# pse84_a0 register map
Vendor: Infineon Technologies; Series: PSE84_A0; File version: 1.0
CPU: CM33 r0p1, little endian, MPU, FPU, VTOR, 3 interrupt priority bits
Registers are 32-bit, read-write, reset 0x0 unless marked. A register's access mark holds for its fields unless they carry their own. Offsets are from the block's base; [hi:lo] are bit positions; lines under a group give offsets from that group.

## USBHS (part 7 of 7) — Regmap for both Subsystem and Controller IP
Base 0x44900000
0x40000 SS group — USBHS Subsystem, Controller, PHY control,configuration and status registers
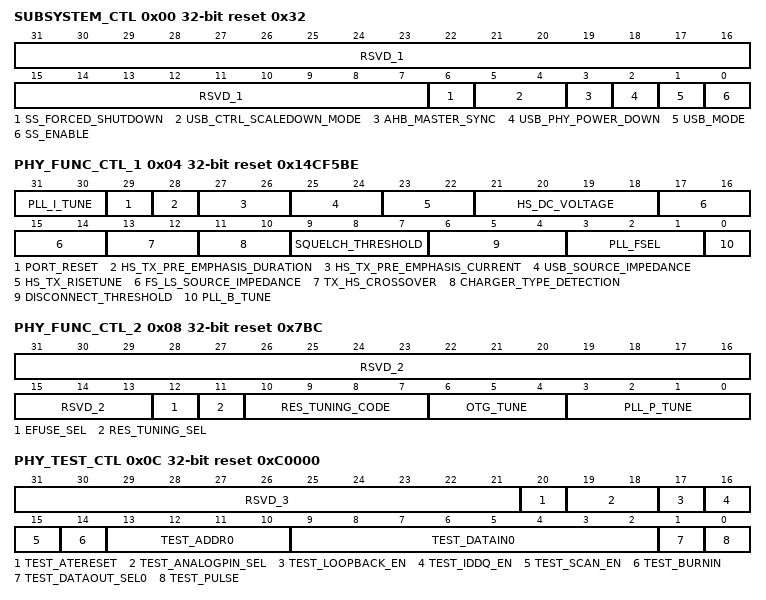
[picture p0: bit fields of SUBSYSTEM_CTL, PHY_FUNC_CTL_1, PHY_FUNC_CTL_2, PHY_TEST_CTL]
  0x00 SUBSYSTEM_CTL reset 0x32 — Subsystem level control register
    [31:7] RSVD_1
    [6] SS_FORCED_SHUTDOWN — 1'b1: Forces shutdown of Controller resulting in data corruption from/to of Controller to the PHY resulting in USBHS moving to Q-state by accepting Q-channel request. 1'b0: Subsystem in normal operational mode.
    [5:4] USB_CTRL_SCALEDOWN_MODE — 2'b00: Disables all scale-downs,actual timing value are used for synthesis.2'b01:Enables scale-down of all timing except Device mode.2'b10:Enables scale-down of Device mode suspend and resume timing values only.2'b11:Enables bit 0 and 1 scale-down timing values useful for simulations
    [3] AHB_MASTER_SYNC — 1'b1:Enables AHB Master interface of Controller synchronisation to 'mmio_clk_hf' clock.1'b0: Disables AHB5 Master interface synchronisation such that 100 MHz generated out of 'clk_hf' is used.
    [2] USB_PHY_POWER_DOWN — 1'b1:In the PHY during Sleep , the bias,PLL blocks are powered down and in Suspend , REFCLK_LOGIC also powered down. 1'b0:All the three blocks remain powered during Sleep and Suspend modes.
    [1] USB_MODE — 1'b1:USB Subsystem is set to Host mode.1'b0: Subsystem is set to Device mode.
    [0] SS_ENABLE — 1'b1: Subsystem enable after power on reset to indicate both analog and digital power supply,all top level clocks,resets are stable to configure Controller core mode. 1'b0: Subsystem disable
  0x04 PHY_FUNC_CTL_1 reset 0x14CF5BE — Subsystem level- PHY functional mode control register 1
    [31:30] PLL_I_TUNE — PHY PLL Integral path tune.2'b00:1.0x ,2'b01:2.0x,2'b10:3.0x,2'b11:4.0x
    [29] PORT_RESET — PHY port reset. 1'b0:Transmitter ,Receiver FSMs are operational and line_state becomes sequential after 11 PHY clock cycles. 1'b1:Transmitter ,Receiver FSMs are reset and line_state combinatorily reflects the state of SE-receivers.
    [28] HS_TX_PRE_EMPHASIS_DURATION — HS transmitter pre-emphasis duration control. 1'b0:2x long pre-emphasis, 1'b1:1x short pre-emphasis.
    [27:26] HS_TX_PRE_EMPHASIS_CURRENT — HS transmitter pre-emphasis current control. 2'b00:0 ,2'b01:1x,2'b10:2x,2'b11:3x
    [25:24] USB_SOURCE_IMPEDANCE — USB source impedance (Ohm). 2'b00:+3.01, 2'b01:0, 2'b10:2.68, 2'b11:5.01
    [23:22] HS_TX_RISETUNE — HS transmitter rise/fall time( percent).2'b00:+1.06, 2'b01:0, 2'b10:-1.9, 2'b11:-2.33
    [21:18] HS_DC_VOLTAGE — HS DC voltage( percent) level adjustment.4'b000:-6.06,4'b0001:-4.04,4'b0010:-2.03,4'b0011:0
    [17:14] FS_LS_SOURCE_IMPEDANCE
    [13:12] TX_HS_CROSSOVER
    [11:10] CHARGER_TYPE_DETECTION — Data detect voltage threshold adjustment during charger type detection. 2'b00:+10.2 percent , 2'b01:0 percent, 2'b10:-10.2 percent, 2'b11: -20.75 percent
    [9:7] SQUELCH_THRESHOLD — Voltage level threshold to detect valid High-Speed data. 3'b000 : +16.9 percent , 3'b001: +10.95 percent , 3'b010: +5.86 percent, 3'b011:0 percent,3'b100: -5.03 percent, 3'b101: -11.41 percent, 3'b110 : -16.92 percent ,3'b111: -22.75 percent.
    [6:4] DISCONNECT_THRESHOLD — Voltage level threshold to detect a disconnect event. 3'b000 : -4.33 percent , 3'b001: -2.93 percent , 3'b010: -1.48 percent, 3'b011:0 percent,3'b100: +1.36 percent, 3'b101: + 2.98 percent, 3'b110 : +4.67 percent ,3'b111: +6.45 percent.
    [3:1] PLL_FSEL — PHY PLL reference clock frequency selection(MHz). If BANDWIDTH_TUNE is 1'b0 ,then 3'b000 is 9.6, 3'b001 is 10, 3'b010 is 12 and 3'b111 is 50 .Else 3'b000 is 19.2, 3'b001 is 20, 3'b010 is 24. Other combination of values are invlaid.
    [0] PLL_B_TUNE — PHY PLL reference clock frequency tuning enable to double bandwidth of the PLL 1'b1: Enable ,1'b0: Disable
  0x08 PHY_FUNC_CTL_2 reset 0x7BC — Subsystem level- PHY functional mode control register 2
    [31:13] RSVD_2
    [12] EFUSE_SEL — This signal selects the tuning method for the high-speed DP0 and DM0 source impedance of the USB 2.0 femtoPHY.1: Internal digital calibration code is used for tuning the high-speed source impedance.0: The RCALCODE0[3:0] value is used for tuning the high-speed source impedance.
    [11] RES_TUNING_SEL — This signal selects the tuning method for the high-speed DP0 and DM0 source impedance of the USB 2.0 femtoPHY.1: Internal digital calibration code is used for tuning the high-speed source impedance.0: The RCALCODE0[3:0] value is used for tuning the high-speed source impedance.
    [10:7] RES_TUNING_CODE — This bus is the resistor tuning code for the high-speed DP0 and DM0 source impedance of the USB 2.0 femtoPHY. The input values for this bus could be driven by ATE during characterization or production, and by an EFUSE block during product operation. All values from 4'b1111 to 4'b0000 are valid.4'b1111: provides lowest impedance on DP0 and DM0.4'b0000: provides the highest impedance on DP0 and DM0
    [6:4] OTG_TUNE — VBUS Valid Threshold Adjustment.3'b011: 0, (design default)
    [3:0] PLL_P_TUNE — PHY PLL Proportioanl path tune.4'b1100:10.0x(design default)
  0x0C PHY_TEST_CTL reset 0xC0000 — Subsystem level- PHY test mode control register
    [31:21] RSVD_3
    [20] TEST_ATERESET — USB PHY test mode ATE reset. 1'b1 : Disables PHYCLOCK0 ,FREECLK outputs. 1'b0:PHYCLOCK0 ,FREECLK outputs are available within(maximum duration) 16.33 ns if UTMI+ interface is 8 bits else 24.66 ns
    [19:18] TEST_ANALOGPIN_SEL
    [17] TEST_LOOPBACK_EN — USB PHY loopback test control 1'b1: Enable.1'b0:Disable
    [16] TEST_IDDQ_EN — USB PHY IDDQ test control 1'b1: Enable.1'b0:Disable
    [15] TEST_SCAN_EN — USB PHY scan test (at-speed and stuck-at fault)mode. 1'b1: Enable.1'b0:Disable
    [14] TEST_BURNIN — USB PHY test mode burn-in control. 1'b1: Enable(PHY performs power on reset,enters HS loopback mode to transmit alternate 1's and 0's until disabled. 1'b0:Disable
    [13:10] TEST_ADDR0 — USB PHY test mode register address bus.
    [9:2] TEST_DATAIN0 — USB PHY test mode data write bus. Bits 0 to 3 are data, 4 to 7 are corresponding write enables
    [1] TEST_DATAOUT_SEL0 — USB PHY test mode data output selection. 1'b1: Mode-defined test register contents are output. 1'b0:Mode-defined, internally generated signals are ouptut.
    [0] TEST_PULSE — USB PHY test mode non-continous clocking signal
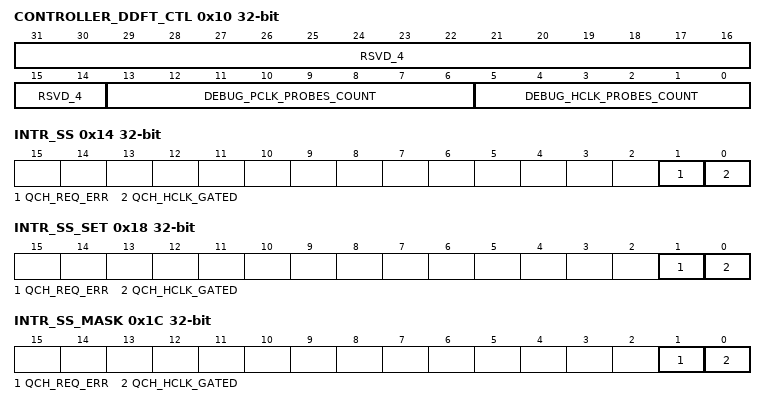
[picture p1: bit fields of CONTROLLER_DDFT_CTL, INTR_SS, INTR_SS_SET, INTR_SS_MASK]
  0x10 CONTROLLER_DDFT_CTL — Subsystem level- Controller DDFT control register
    [31:14] RSVD_4
    [13:6] DEBUG_PCLK_PROBES_COUNT — USB Controller PHY clock domain internal signal probe counter value for debug[8'd0 to 8'd218]
    [5:0] DEBUG_HCLK_PROBES_COUNT — USB Controller AHB clock domain internal signal probe counter value for debug[6'd0 to 6'd61]
  0x14 INTR_SS — Subsystem level- Interrupt register
    [1] QCH_REQ_ERR — Subsystem and USB Controller AHB clock are gated after Q-state request is accepted either after end of transfer or forceful shutdown request from APPCPUSS
    [0] QCH_HCLK_GATED — Subsystem and USB Controller AHB clock are gated after Q-state request is accepted either after end of transfer or forceful shutdown request from APPCPUSS
  0x18 INTR_SS_SET — Subsystem level- Interrupt set register
    [1] QCH_REQ_ERR — Write 1'b1 to set corresponding bit in interrupt register.
    [0] QCH_HCLK_GATED — Write 1'b1 to set corresponding bit in interrupt register.
  0x1C INTR_SS_MASK — Subsystem level- Interrupt mask register
    [1] QCH_REQ_ERR — Mask bit for corresponding bit in interrupt register.
    [0] QCH_HCLK_GATED — Mask bit for corresponding bit in interrupt register.
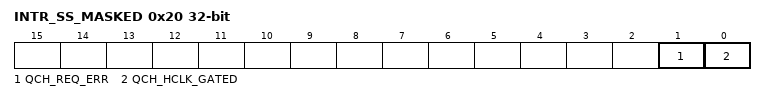
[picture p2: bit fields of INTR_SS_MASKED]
  0x20 INTR_SS_MASKED ro — Subsystem level- Interrupt masked register
    [1] QCH_REQ_ERR — Logical and of corresponding interrupt and mask bits.
    [0] QCH_HCLK_GATED — Logical and of corresponding interrupt and mask bits.SW need to set CTL.SS_FORCED_SHUTDOWN bit one clk_pwr cycle before PERI asserts Qrequest otherwise subsystem will deny the Qrequest. This interrupt indicates Subsystem accepts Q-state request and its functional clock (mmio_clk_sys) is internally gated and is in DEEPSLEEP power mode. Its PERI/SRSS responsbility to gate clk_pwr,clk_phy_pll_ref and assert rst_pwr_act_n as required. Renabling Subsystem requires first QExit->QEntry from PERI then Subsystem programming.
